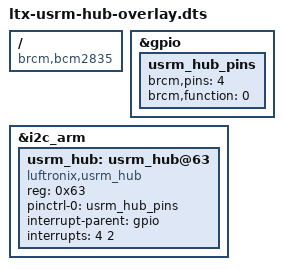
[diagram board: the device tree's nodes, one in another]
// Definitions for USRM-HUB sonars hub from Luftronix.

/dts-v1/;
/plugin/;

/ {
	compatible = "brcm,bcm2835", "brcm,bcm2708", "brcm,bcm2709";

	fragment@0 {
		target = <&gpio>;
		__overlay__ {
			usrm_hub_pins: usrm_hub_pins {
				brcm,pins = <4>;		/* GPIO BCM4 */
				brcm,function = <0>;	/* GPIO in */
			};
		};
	};


	fragment@1 {
		target = <&i2c_arm>;
		__overlay__ {
			#address-cells = <1>;
			#size-cells = <0>;
			status = "okay";

			usrm_hub: usrm_hub@63 {
				compatible = "luftronix,usrm_hub";
				reg = <0x63>;
				pinctrl-names = "default";
				pinctrl-0 = <&usrm_hub_pins>;
				interrupt-parent = <&gpio>;
				interrupts = <4 2>;		/* GPIO BCM4, 2 = high-to-low edge triggered */
				status = "okay";
			};
		};
	};
	
	__overrides__ {
		gpiopin = <&usrm_hub_pins>,"brcm,pins:0",
				<&usrm_hub>,"interrupts:0";
		addr = <&usrm_hub>,"reg:0";
	};
};

